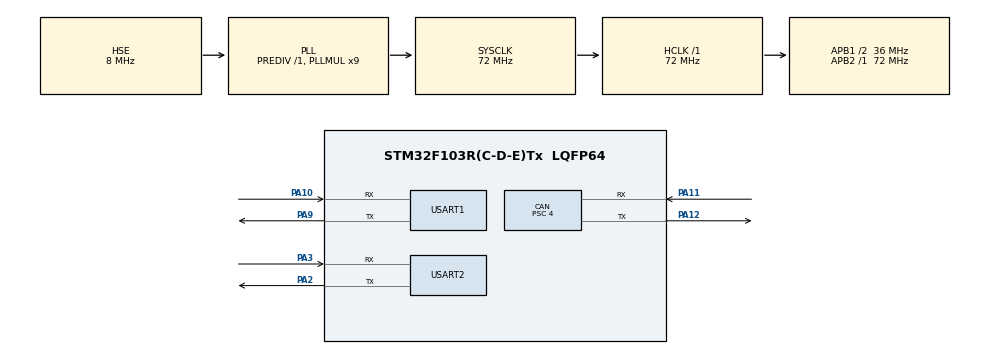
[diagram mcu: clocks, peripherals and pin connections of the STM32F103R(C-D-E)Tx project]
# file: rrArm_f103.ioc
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CAN.AWUM=ENABLE
CAN.BS1=CAN_BS1_5TQ
CAN.BS2=CAN_BS2_3TQ
CAN.CalculateBaudRate=1000000
CAN.CalculateTimeBit=1000
CAN.CalculateTimeQuantum=111.11111111111111
CAN.Prescaler=4
CAN.TXFP=ENABLE
Dma.Request0=USART1_RX
Dma.Request1=USART1_TX
Dma.Request2=USART2_RX
Dma.Request3=USART2_TX
Dma.USART1_RX.0.Direction=DMA_PERIPH_TO_MEMORY
Dma.USART1_RX.0.Instance=DMA1_Channel5
Dma.USART1_RX.0.MemDataAlignment=DMA_MDATAALIGN_BYTE
Dma.USART1_RX.0.MemInc=DMA_MINC_ENABLE
Dma.USART1_RX.0.Mode=DMA_NORMAL
Dma.USART1_RX.0.PeriphDataAlignment=DMA_PDATAALIGN_BYTE
Dma.USART1_RX.0.PeriphInc=DMA_PINC_DISABLE
Dma.USART1_RX.0.Priority=DMA_PRIORITY_LOW
Dma.USART1_TX.1.Direction=DMA_MEMORY_TO_PERIPH
Dma.USART1_TX.1.Instance=DMA1_Channel4
Dma.USART1_TX.1.MemDataAlignment=DMA_MDATAALIGN_BYTE
Dma.USART1_TX.1.MemInc=DMA_MINC_ENABLE
Dma.USART1_TX.1.Mode=DMA_NORMAL
Dma.USART1_TX.1.PeriphDataAlignment=DMA_PDATAALIGN_BYTE
Dma.USART1_TX.1.PeriphInc=DMA_PINC_DISABLE
Dma.USART1_TX.1.Priority=DMA_PRIORITY_LOW
Dma.USART2_RX.2.Direction=DMA_PERIPH_TO_MEMORY
Dma.USART2_RX.2.Instance=DMA1_Channel6
Dma.USART2_RX.2.MemDataAlignment=DMA_MDATAALIGN_BYTE
Dma.USART2_RX.2.MemInc=DMA_MINC_ENABLE
Dma.USART2_RX.2.Mode=DMA_NORMAL
Dma.USART2_RX.2.PeriphDataAlignment=DMA_PDATAALIGN_BYTE
Dma.USART2_RX.2.PeriphInc=DMA_PINC_DISABLE
Dma.USART2_RX.2.Priority=DMA_PRIORITY_LOW
Dma.USART2_TX.3.Direction=DMA_MEMORY_TO_PERIPH
Dma.USART2_TX.3.Instance=DMA1_Channel7
Dma.USART2_TX.3.MemDataAlignment=DMA_MDATAALIGN_BYTE
Dma.USART2_TX.3.MemInc=DMA_MINC_ENABLE
Dma.USART2_TX.3.Mode=DMA_NORMAL
Dma.USART2_TX.3.PeriphDataAlignment=DMA_PDATAALIGN_BYTE
Dma.USART2_TX.3.PeriphInc=DMA_PINC_DISABLE
Dma.USART2_TX.3.Priority=DMA_PRIORITY_LOW
FREERTOS.Tasks01=defaultTask,24,128,StartDefaultTask,Default,NULL,Dynamic,NULL,NULL
Mcu.Family=STM32F1
Mcu.Name=STM32F103R(C-D-E)Tx
Mcu.Package=LQFP64
NVIC.CAN1_RX1_IRQn=true\:5\:0\:false\:false\:true\:true\:true\:true\:true
NVIC.DMA1_Channel4_IRQn=true\:5\:0\:false\:false\:true\:true\:false\:true\:true
NVIC.DMA1_Channel5_IRQn=true\:5\:0\:false\:false\:true\:true\:false\:true\:true
NVIC.DMA1_Channel6_IRQn=true\:5\:0\:false\:false\:true\:true\:false\:true\:true
NVIC.DMA1_Channel7_IRQn=true\:5\:0\:false\:false\:true\:true\:false\:true\:true
NVIC.PriorityGroup=NVIC_PRIORITYGROUP_4
NVIC.TIM6_IRQn=true\:15\:0\:false\:false\:true\:false\:false\:true\:true
NVIC.TimeBase=TIM6_IRQn
NVIC.TimeBaseIP=TIM6
NVIC.USART1_IRQn=true\:5\:0\:false\:false\:true\:true\:true\:true\:true
NVIC.USART2_IRQn=true\:5\:0\:false\:false\:true\:true\:true\:true\:true
NVIC.USB_HP_CAN1_TX_IRQn=true\:5\:0\:false\:false\:true\:true\:true\:true\:true
NVIC.USB_LP_CAN1_RX0_IRQn=true\:5\:0\:false\:false\:true\:true\:true\:true\:true
PA10.Mode=Asynchronous
PA10.Signal=USART1_RX
PA11.Mode=CAN_Activate
PA11.Signal=CAN_RX
PA12.Mode=CAN_Activate
PA12.Signal=CAN_TX
PA13.Mode=Serial_Wire
PA13.Signal=SYS_JTMS-SWDIO
PA14.Mode=Serial_Wire
PA14.Signal=SYS_JTCK-SWCLK
PA2.Mode=Asynchronous
PA2.Signal=USART2_TX
PA3.Mode=Asynchronous
PA3.Signal=USART2_RX
PA9.Mode=Asynchronous
PA9.Signal=USART1_TX
PD0-OSC_IN.Mode=HSE-External-Oscillator
PD0-OSC_IN.Signal=RCC_OSC_IN
PD1-OSC_OUT.Mode=HSE-External-Oscillator
PD1-OSC_OUT.Signal=RCC_OSC_OUT
ProjectManager.HeapSize=0x200
ProjectManager.StackSize=0x400
ProjectManager.TargetToolchain=STM32CubeIDE
RCC.AHBFreq_Value=72000000
RCC.APB1CLKDivider=RCC_HCLK_DIV2
RCC.APB1Freq_Value=36000000
RCC.APB1TimFreq_Value=72000000
RCC.APB2Freq_Value=72000000
RCC.APB2TimFreq_Value=72000000
RCC.HCLKFreq_Value=72000000
RCC.PLLMUL=RCC_PLL_MUL9
RCC.PLLSourceVirtual=RCC_PLLSOURCE_HSE
RCC.SYSCLKFreq_VALUE=72000000
RCC.SYSCLKSource=RCC_SYSCLKSOURCE_PLLCLK
RCC.USBFreq_Value=72000000
USART1.VirtualMode=VM_ASYNC
USART2.VirtualMode=VM_ASYNC
VP_FREERTOS_VS_CMSIS_V2.Mode=CMSIS_V2
VP_SYS_VS_tim6.Mode=TIM6
board=custom

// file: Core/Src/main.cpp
/* USER CODE BEGIN Header */
/**
  ******************************************************************************
  * @file           : main.c
  * @brief          : Main program body
  ******************************************************************************
  * @attention
  *
  * Copyright (c) 2026 STMicroelectronics.
  * All rights reserved.
  *
  * This software is licensed under terms that can be found in the LICENSE file
  * in the root directory of this software component.
  * If no LICENSE file comes with this software, it is provided AS-IS.
  *
  ******************************************************************************
  */
/* USER CODE END Header */
#include "main.h"
#include "cmsis_os.h"
#include "can.h"
#include "dma.h"
#include "usart.h"
#include "gpio.h"

void SystemClock_Config(void);
void MX_FREERTOS_Init(void);

int main(void)
{

  /* MCU Configuration--------------------------------------------------------*/

  /* Reset of all peripherals, Initializes the Flash interface and the Systick. */
  HAL_Init();

  /* Configure the system clock */
  SystemClock_Config();

  /* Initialize all configured peripherals */
  MX_GPIO_Init();
  MX_DMA_Init();
  MX_USART1_UART_Init();
  MX_USART2_UART_Init();
  MX_CAN_Init();
  /* USER CODE BEGIN 2 */
  CAN_ConfigFilter();
  HAL_CAN_Start(&hcan);
  HAL_CAN_ActivateNotification(&hcan, CAN_IT_RX_FIFO0_MSG_PENDING);
  /* USER CODE END 2 */

  /* Init scheduler */
//  osKernelInitialize();

  /* Call init function for freertos objects (in cmsis_os2.c) */
  MX_FREERTOS_Init();

  /* Start scheduler */
//  osKernelStart();
  vTaskStartScheduler();

  /* We should never get here as control is now taken by the scheduler */

  /* Infinite loop */
  while (1)
  {

  }
}

void SystemClock_Config(void)
{
  RCC_OscInitTypeDef RCC_OscInitStruct = {0};
  RCC_ClkInitTypeDef RCC_ClkInitStruct = {0};

  /** Initializes the RCC Oscillators according to the specified parameters
  * in the RCC_OscInitTypeDef structure.
  */
  RCC_OscInitStruct.OscillatorType = RCC_OSCILLATORTYPE_HSE;
  RCC_OscInitStruct.HSEState = RCC_HSE_ON;
  RCC_OscInitStruct.HSEPredivValue = RCC_HSE_PREDIV_DIV1;
  RCC_OscInitStruct.HSIState = RCC_HSI_ON;
  RCC_OscInitStruct.PLL.PLLState = RCC_PLL_ON;
  RCC_OscInitStruct.PLL.PLLSource = RCC_PLLSOURCE_HSE;
  RCC_OscInitStruct.PLL.PLLMUL = RCC_PLL_MUL9;
  if (HAL_RCC_OscConfig(&RCC_OscInitStruct) != HAL_OK)
  {
    Error_Handler();
  }

  /** Initializes the CPU, AHB and APB buses clocks
  */
  RCC_ClkInitStruct.ClockType = RCC_CLOCKTYPE_HCLK|RCC_CLOCKTYPE_SYSCLK
                              |RCC_CLOCKTYPE_PCLK1|RCC_CLOCKTYPE_PCLK2;
  RCC_ClkInitStruct.SYSCLKSource = RCC_SYSCLKSOURCE_PLLCLK;
  RCC_ClkInitStruct.AHBCLKDivider = RCC_SYSCLK_DIV1;
  RCC_ClkInitStruct.APB1CLKDivider = RCC_HCLK_DIV2;
  RCC_ClkInitStruct.APB2CLKDivider = RCC_HCLK_DIV1;

  if (HAL_RCC_ClockConfig(&RCC_ClkInitStruct, FLASH_LATENCY_2) != HAL_OK)
  {
    Error_Handler();
  }
}

void HAL_TIM_PeriodElapsedCallback(TIM_HandleTypeDef *htim)
{
  if (htim->Instance == TIM6)
  {
    HAL_IncTick();
  }
}

void Error_Handler(void)
{
  __disable_irq();
  while (1)
  {
  }
}
